# AE402FA0E5597BE0_CM55_HE_View register map
Vendor: Alif Semiconductor; Series: E4; File version: 1.0
CPU: CM55 r1p0, selectable endian, MPU, FPU, double-precision FPU, DSP, VTOR, 8 interrupt priority bits, 1 SAU regions
Registers are 32-bit, read-write, reset 0x0 unless marked. A register's access mark holds for its fields unless they carry their own. Offsets are from the block's base; [hi:lo] are bit positions; {n}, {i} and the like mark numbered series; 'fields as' and 'values as' point back to an identical list.

## NPU_HE
Base 0x400E1000
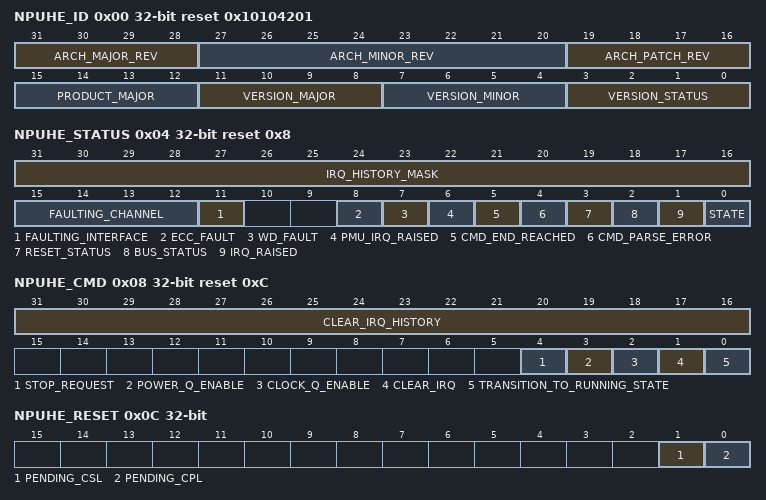
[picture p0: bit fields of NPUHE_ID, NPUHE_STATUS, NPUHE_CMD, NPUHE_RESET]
0x00 NPUHE_ID ro reset 0x10104201 — ID Register
  [31:28] ARCH_MAJOR_REV — This is the major architecture version number, a in the architecture version a.b
  [27:20] ARCH_MINOR_REV — This is the minor architecture version number, b in the architecture version a.b
  [19:16] ARCH_PATCH_REV — This is the patch number of the architecture version a.b
  [15:12] PRODUCT_MAJOR — This is the X-part of the ML00X product number
  [11:8] VERSION_MAJOR — This is the n for the R-part of an RnPn release number
  [7:4] VERSION_MINOR — This is the n for the P-part of an RnPn release number
  [3:0] VERSION_STATUS — This is the version of the product
0x04 NPUHE_STATUS ro reset 0x8 — Status Register
  [31:16] IRQ_HISTORY_MASK — IRQ history mask. This is used for debug purposes. Each IRQ or event operation provides a 16-bit mask which is logically OR-ed into these bits. The bits can be cleared via their counterparts in the NPUHE_CMD[CLEAR_IRQ_HISTORY] field.
  [15:12] FAULTING_CHANNEL — Faulting channel on a bus abort. Read operations: Write operations:
    0=Cmd; 1=IFM; 2=Weights; 3=Bias and Scale; 4=Mem2Mem; 8=OFM; 9=Mem2Mem
  [11] FAULTING_INTERFACE — Faulting interface on bus abort.
    0=AXI-M0; 1=AXI-M1
  [8] ECC_FAULT — ECC state for internal RAMs.
    0=No fault; 1=ECC fault signalled. Can only be cleared by reset.
  [7] WD_FAULT — Weight decoder state. Note: This bit is never set in this product.
    0=No fault; 1=Weight decoder decompression fault signalled. Can only be cleared by reset.
  [6] PMU_IRQ_RAISED — PMU IRQ status.
    0=PMU IRQ not raised; 1=PMU IRQ raised. Can be cleared via the NPUHE_CMD[CLEAR_IRQ] field.
  [5] CMD_END_REACHED — Command stream end status.
    0=End not reached; 1=End reached. Can be cleared by writing NPUHE_QBASE0 / NPUHE_QBASE1 or NPUHE_QSIZE when NPU is in stopped state.
  [4] CMD_PARSE_ERROR — Command stream parsing error status.
    0=No error; 1=Command stream parsing error detected. Can only be cleared by reset.
  [3] RESET_STATUS
    0=NPU is not being reset and can be accessed as normal; 1=Reset is ongoing and only this register can be read (other registers read as 0 and writes are ignored)
  [2] BUS_STATUS
    0=OK; 1=Bus abort detected and processing halted (NPU has reached IDLE state and does not start to process any more commands / AXI transactions). Can only be cleared by reset.
  [1] IRQ_RAISED — Raw IRQ status.
    0=IRQ not raised; 1=IRQ raised. Can be cleared via the NPUHE_CMD[CLEAR_IRQ] field.
  [0] STATE — NPU state.
    0=Stopped; 1=Running
0x08 NPUHE_CMD reset 0xC — Command Register
  [31:16] CLEAR_IRQ_HISTORY — Clears the IRQ history mask. When bit [k] is set, then the corresponding bit [k] of the NPUHE_STATUS[IRQ_HISTORY_MASK] field is cleared.
  [4] STOP_REQUEST — Write 1 to this bit to request STOP after completing any already-started commands.
  [3] POWER_Q_ENABLE — Write 1 to this bit to enable power off using Power Q-interface.
  [2] CLOCK_Q_ENABLE — Write 1 to this bit to enable clock off using Clock Q-interface and enable the master clock gate.
  [1] CLEAR_IRQ — Write 1 to clear the IRQ status in the STATUS register. Writing 0 has no effect.
  [0] TRANSITION_TO_RUNNING_STATE — Write 1 to transition the NPU to running state. Writing 0 has no effect.
0x0C NPUHE_RESET — Reset Register
  [1] PENDING_CSL — Current security level
    0=Secure; 1=Non-secure
  [0] PENDING_CPL — Current privilege level
    0=User; 1=Privileged
0x10 NPUHE_QBASE0 — Queue Base Register 0
  [31:0] QBASE0 — Lower bytes of the base address value for the command stream (4-byte-aligned)
0x14 NPUHE_QBASE1 — Queue Base Register 1
  [31:0] QBASE1 — Upper bytes of the base address value for the command stream (4-byte-aligned)
0x18 NPUHE_QREAD ro — Queue Read Register
  [31:0] QREAD — The read offset (in bytes) of the current command under execution. Multiple of 4 in the range 0 to 16 MB.
0x1C NPUHE_QCONFIG — Queue Configuration Register
  [31:0] QCONFIG — AXI configuration for the command stream in the range 0-3. Same encoding as for NPUHE_REGIONCFG.
0x20 NPUHE_QSIZE — Queue Size Register
  [31:0] QSIZE — Size (in bytes) of the next command stream to be executed by the NPU. Multiple of 4 in the range 0 to 16 MB.
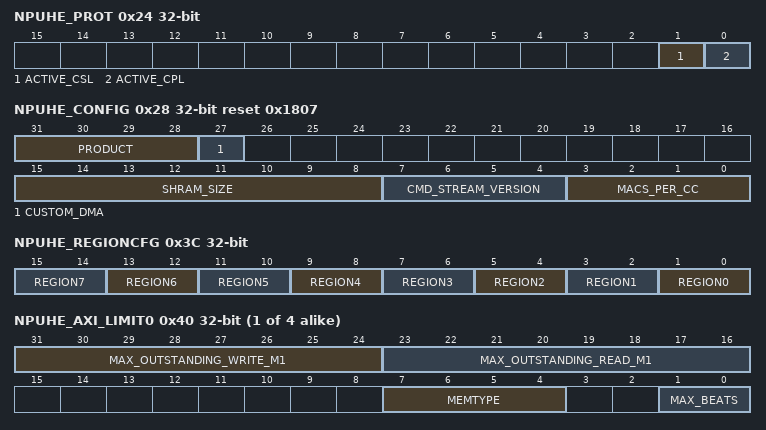
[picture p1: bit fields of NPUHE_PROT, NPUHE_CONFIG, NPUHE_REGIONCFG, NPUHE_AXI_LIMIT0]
0x24 NPUHE_PROT ro — Protection Register
  [1] ACTIVE_CSL — Current security level
    0=Secure; 1=Non-secure
  [0] ACTIVE_CPL — Current privilege level
    0=User; 1=Privileged
0x28 NPUHE_CONFIG ro reset 0x1807 — Module Configuration Register
  [31:28] PRODUCT — Product configuration
  [27] CUSTOM_DMA — Custom DMA configuration
    0=Custom DMA not implemented
  [15:8] SHRAM_SIZE — Total size of internal SHRAM
    24=24KB
  [7:4] CMD_STREAM_VERSION — Command stream version accepted by this NPU
  [3:0] MACS_PER_CC — MACs/clock cycle
    7=128
0x2C NPUHE_LOCK — Lock Register
  [31:0] LOCK — 32-bit value for the lock configuration. To try to claim the lock, write a non-zero ID value and read back to see if the value was accepted. To release the lock (that contains your non-zero ID value), write 0 to the lock register.
0x3C NPUHE_REGIONCFG — Region Configuration Register
  [2n+1:2n] REGION{n} (n=0..7) — Region {n} configuration
{0x40+4i} NPUHE_AXI_LIMIT{i} (i=0..3) — AXI Limit Register {i}
  [31:24] MAX_OUTSTANDING_WRITE_M1 — Maximum number of [outstanding AXI write transactions - 1] in range 0 to 15
  [23:16] MAX_OUTSTANDING_READ_M1 — Maximum number of [outstanding AXI read transactions - 1] in range 0 to 31
  [7:4] MEMTYPE — Memory type
    0=Device Non-Bufferable; 1=Device Bufferable; 2=Normal, Non-Cacheable, Non-Bufferable; 3=Normal, Non-Cacheable, Bufferable; 4=Write Through, No Allocate; 5=Write Through, Read Allocate; 6=Write Through, Write Allocate; 7=Write Through, Read and Write Allocate; 8=Write Back, No Allocate; 9=Write Back, Read Allocate; 10=Write Back, Write Allocate; 11=Write Back, Read and Write Allocate
  [1:0] MAX_BEATS — Burst split alignment
    0=64 bytes; 1=128 bytes; 2=256 bytes
0x80 NPUHE_BASEP0 — Base Pointer Register 0
  [31:0] ADDR_WORD — The low word of the 64-bit address
0x84 NPUHE_BASEP1 — Base Pointer Register 1
  [31:0] ADDR_WORD — The high word of the 64-bit address
0x88 NPUHE_BASEP2 — Base Pointer Register 2
  [31:0] ADDR_WORD — The low word of the 64-bit address
0x8C NPUHE_BASEP3 — Base Pointer Register 3
  [31:0] ADDR_WORD — The high word of the 64-bit address
0x90 NPUHE_BASEP4 — Base Pointer Register 4
  [31:0] ADDR_WORD — The low word of the 64-bit address
0x94 NPUHE_BASEP5 — Base Pointer Register 5
  [31:0] ADDR_WORD — The high word of the 64-bit address
0x98 NPUHE_BASEP6 — Base Pointer Register 6
  [31:0] ADDR_WORD — The low word of the 64-bit address
0x9C NPUHE_BASEP7 — Base Pointer Register 7
  [31:0] ADDR_WORD — The high word of the 64-bit address
0xA0 NPUHE_BASEP8 — Base Pointer Register 8
  [31:0] ADDR_WORD — The low word of the 64-bit address
0xA4 NPUHE_BASEP9 — Base Pointer Register 9
  [31:0] ADDR_WORD — The high word of the 64-bit address
0xA8 NPUHE_BASEP10 — Base Pointer Register 10
  [31:0] ADDR_WORD — The low word of the 64-bit address
0xAC NPUHE_BASEP11 — Base Pointer Register 11
  [31:0] ADDR_WORD — The high word of the 64-bit address
0xB0 NPUHE_BASEP12 — Base Pointer Register 12
  [31:0] ADDR_WORD — The low word of the 64-bit address
0xB4 NPUHE_BASEP13 — Base Pointer Register 13
  [31:0] ADDR_WORD — The high word of the 64-bit address
0xB8 NPUHE_BASEP14 — Base Pointer Register 14
  [31:0] ADDR_WORD — The low word of the 64-bit address
0xBC NPUHE_BASEP15 — Base Pointer Register 15
  [31:0] ADDR_WORD — The high word of the 64-bit address
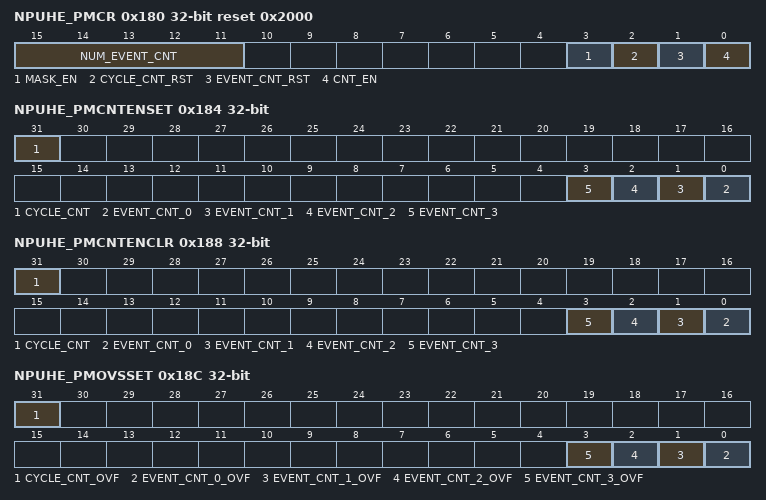
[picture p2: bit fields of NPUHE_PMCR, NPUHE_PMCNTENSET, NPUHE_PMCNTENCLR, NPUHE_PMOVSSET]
0x180 NPUHE_PMCR reset 0x2000 — Performance Monitor Control Register
  [15:11] NUM_EVENT_CNT ro — Number of PMU event counters (4 event counters are available)
  [3] MASK_EN — Allows to enable/disable PMU by command stream operation NPU_OP_PMU_MASK. Note that the [CNT_EN] field in this register must be enabled for the PMU to be active.
  [2] CYCLE_CNT_RST wo — Reset PMU cycle counter. Writing 1 to this field resets the cycle counter. If the cycle counter is active, it will continue counting after reset.
  [1] EVENT_CNT_RST wo — Reset PMU event counter. Writing 1 to this field resets all event counters. If any counter is active, it will continue counting after reset.
  [0] CNT_EN — Enable PMU. This is the master switch. When the switch is disabled, the PMU is always off. Writing 1 to this field enables PMU operation.
0x184 NPUHE_PMCNTENSET — Performance Monitor Count Enable Set Register
  [31] CYCLE_CNT — Enable PMU cycle counter.
    0=When read, it means the cycle counter is disabled. When written, it has no effect.; 1=When read, it means the cycle counter is enabled. When written, it enables the cycle counter.
  [n] EVENT_CNT_{n} (n=0..3) — Enable PMU event counter {n}.
    0=When read, it means the event counter is disabled. When written, it has no effect.; 1=When read, it means the event counter is enabled. When written, it enables the event counter.
0x188 NPUHE_PMCNTENCLR — Performance Monitor Count Enable Clear Register
  [31] CYCLE_CNT — Disable PMU cycle counter.
    0=When read, it means the cycle counter is disabled. When written, it has no effect.; 1=When read, it means the cycle counter is enabled. When written, it disables the cycle counter.
  [n] EVENT_CNT_{n} (n=0..3) — Disable PMU event counter {n}.
    0=When read, it means the event counter is disabled. When written, it has no effect.; 1=When read, it means the event counter is enabled. When written, it disables the event counter.
0x18C NPUHE_PMOVSSET — Performance Monitor Overflow Status Set Register
  [31] CYCLE_CNT_OVF — Set overflow for PMU cycle counter.
    0=When read, it means the cycle counter has not overflowed. When written, it has no effect.; 1=When read, it means the cycle counter has overflowed. When written, it sets the overflow bit to 1.
  [n] EVENT_CNT_{n}_OVF (n=0..3) — Set overflow for PMU event counter {n}.
    0=When read, it means the event counter has not overflowed. When written, it has no effect.; 1=When read, it means the event counter has overflowed. When written, it sets the overflow bit to 1.
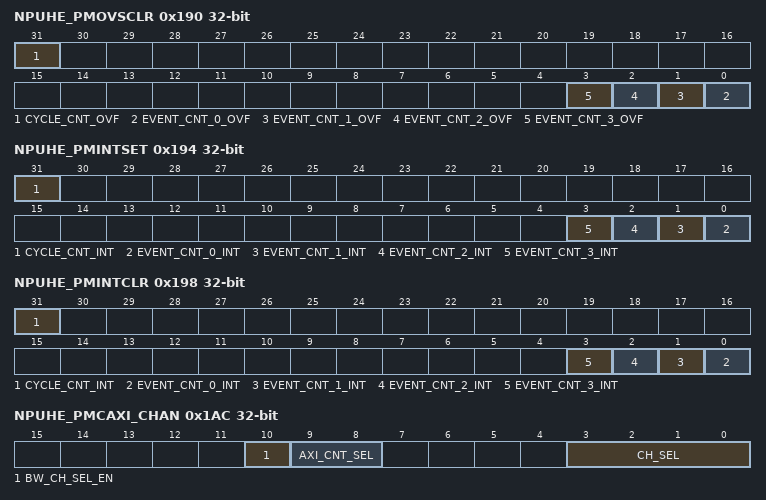
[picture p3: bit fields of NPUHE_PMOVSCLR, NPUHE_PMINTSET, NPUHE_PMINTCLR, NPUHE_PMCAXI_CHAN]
0x190 NPUHE_PMOVSCLR — Performance Monitor Overflow Status Clear Register
  [31] CYCLE_CNT_OVF — Clear overflow for PMU cycle counter.
    0=When read, it means the cycle counter has not overflowed. When written, it has no effect.; 1=When read, it means the cycle counter has overflowed. When written, it clears the overflow bit to 0.
  [n] EVENT_CNT_{n}_OVF (n=0..3) — Clear overflow for PMU event counter {n}.
    0=When read, it means the event counter has not overflowed. When written, it has no effect.; 1=When read, it means the event counter has overflowed. When written, it clears the overflow bit to 0.
0x194 NPUHE_PMINTSET — Performance Monitor Interrupt Set Register
  [31] CYCLE_CNT_INT — Enable overflow interrupt request for PMU cycle counter. interrupt request.
    0=When read, it means the cycle counter overflow interrupt request is disabled. When written, it has no effect.; 1=When read, it means the cycle counter overflow interrupt request is enabled. When written, it enables the cycle count overflow
  [n] EVENT_CNT_{n}_INT (n=0..3) — Enable overflow interrupt request for PMU event counter {n}. interrupt request.
    0=When read, it means the event counter overflow interrupt request is disabled. When written, it has no effect.; 1=When read, it means the event counter overflow interrupt request is enabled. When written, it enables the event count overflow
0x198 NPUHE_PMINTCLR — Performance Monitor Interrupt Clear Register
  [31] CYCLE_CNT_INT — Disable overflow interrupt request for PMU cycle counter. overflow interrupt request.
    0=When read, it means the cycle counter overflow interrupt-request is disabled. When written, it has no effect.; 1=When read, it means the cycle counter overflow interrupt-request is enabled. When written, it disables the cycle count
  [n] EVENT_CNT_{n}_INT (n=0..3) — Disable overflow interrupt request for PMU event counter {n}. overflow interrupt request.
    0=When read, it means the event counter overflow interrupt-request is disabled. When written, it has no effect.; 1=When read, it means the event counter overflow interrupt-request is enabled. When written, it disables the event count
0x1A0 NPUHE_PMCCNTR_LO — Performance Monitor Cycle Count Low Register
  [31:0] CYCLE_CNT_LO — Cycle count low
0x1A4 NPUHE_PMCCNTR_HI — Performance Monitor Cycle Count High Register
  [15:0] CYCLE_CNT_HI — Cycle count high
0x1AC NPUHE_PMCAXI_CHAN — Performance Monitor AXI Channel Select Register
  [10] BW_CH_SEL_EN — Enable bandwidth channel selector
    0=AXI BW events measured for all channels; 1=AXI BW events measured for channel specified by [CH_SEL]
  [9:8] AXI_CNT_SEL — Select AXI counter to monitor for latency measurements A maximum of two separate outstanding transaction queues can be connected to each AXI interface. The counters are used to express the maximum number of outstanding jobs per queue.
    0=AXI counter 0 (AXI port 0, outstanding counter 0); 1=AXI counter 1 (AXI port 0, outstanding counter 1); 2=AXI counter 2 (AXI port 1, outstanding counter 0); 3=AXI counter 3 (AXI port 1, outstanding counter 1)
  [3:0] CH_SEL — Select channel to monitor for bandwidth or latency measurements Read operations: Write operations:
    values as NPUHE_STATUS.FAULTING_CHANNEL
{0x300+4i} NPUHE_PMEVCNTR{i} (i=0..3) — Performance Monitor Event Count Register {i}
  [31:0] EV_CNTR — Event counter value
{0x380+4i} NPUHE_PMEVTYPER{i} (i=0..3) — Performance Monitor Event Type Register {i}
  [9:0] EV_TYPE — Event type. For field encoding (list of supported PMU events), refer to the Arm(R) Ethos(TM)-U55 NPU Technical Reference Manual.
0xFD0 NPUHE_PID4 ro reset 0x4 — Peripheral ID Register 4
  [31:0] PID4 — Byte 4 of Peripheral ID (lower 8 bits valid)
{0xFC0+4i} NPUHE_PID{i} ro (i=5..7) — Peripheral ID Register {i}
  [31:0] PID{i} — Byte {i} of Peripheral ID (lower 8 bits valid)
0xFE0 NPUHE_PID0 ro reset 0x80 — Peripheral ID Register 0
  [31:0] PID0 — Byte 0 of Peripheral ID (lower 8 bits valid)
0xFE4 NPUHE_PID1 ro reset 0xB5 — Peripheral ID Register 1
  [31:0] PID1 — Byte 1 of Peripheral ID (lower 8 bits valid)
0xFE8 NPUHE_PID2 ro reset 0xB — Peripheral ID Register 2
  [31:0] PID2 — Byte 2 of Peripheral ID (lower 8 bits valid)
0xFEC NPUHE_PID3 ro — Peripheral ID Register 3
  [31:0] PID3 — Byte 3 of Peripheral ID (lower 8 bits valid)
0xFF0 NPUHE_CID0 ro reset 0xD — Component ID Register 0
  [31:0] CID0 — Byte 0 of Component ID (lower 8 bits valid)
0xFF4 NPUHE_CID1 ro reset 0xF0 — Component ID Register 1
  [31:0] CID1 — Byte 1 of Component ID (lower 8 bits valid)
0xFF8 NPUHE_CID2 ro reset 0x5 — Component ID Register 2
  [31:0] CID2 — Byte 2 of Component ID (lower 8 bits valid)
0xFFC NPUHE_CID3 ro reset 0xB1 — Component ID Register 3
  [31:0] CID3 — Byte 3 of Component ID (lower 8 bits valid)
